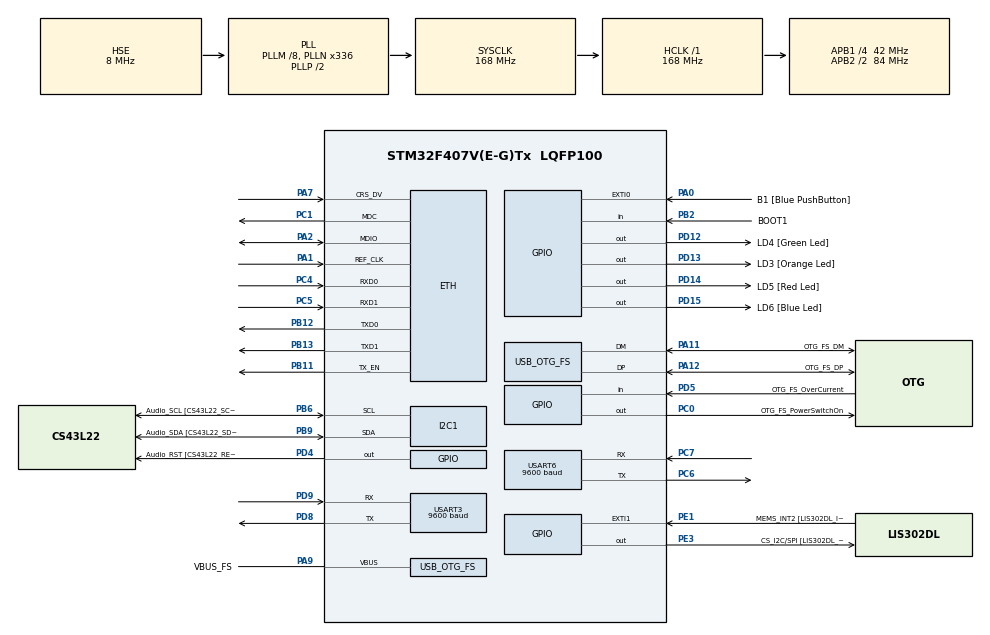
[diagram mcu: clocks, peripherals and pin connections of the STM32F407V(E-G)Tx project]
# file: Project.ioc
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ETH.MACAddr=00\:80\:E1\:00\:00\:01
ETH.MediaInterface=ETH_MEDIA_INTERFACE_RMII
ETH.PhyAddress=0
LWIP.GATEWAY_ADDRESS=192.168.001.254
LWIP.IP_ADDRESS=169.254.039.001
LWIP.LWIP_DHCP=0
LWIP.LWIP_HTTPD=1
LWIP.LWIP_HTTPD_CUSTOM_FILES=1
LWIP.LWIP_HTTPD_DYNAMIC_HEADERS=1
LWIP.NETMASK_ADDRESS=255.255.000.000
LWIP.Version=v2.0.3_Cube
Mcu.Family=STM32F4
Mcu.Name=STM32F407V(E-G)Tx
Mcu.Package=LQFP100
NVIC.OTG_FS_IRQn=true\:0\:0\:false\:false\:true\:true\:true
NVIC.PriorityGroup=NVIC_PRIORITYGROUP_0
NVIC.TIM2_IRQn=true\:0\:0\:false\:false\:true\:true\:true
NVIC.USART3_IRQn=true\:0\:0\:false\:false\:true\:true\:true
NVIC.USART6_IRQn=true\:0\:0\:false\:false\:true\:true\:true
PA0-WKUP.GPIO_Label=B1 [Blue PushButton]
PA0-WKUP.GPIO_ModeDefaultEXTI=GPIO_MODE_EVT_RISING
PA0-WKUP.GPIO_PuPd=GPIO_NOPULL
PA0-WKUP.Signal=GPXTI0
PA1.Mode=RMII
PA1.Signal=ETH_REF_CLK
PA10.GPIO_Label=OTG_FS_ID
PA10.GPIO_Mode=GPIO_MODE_AF_PP
PA10.GPIO_PuPd=GPIO_NOPULL
PA10.GPIO_Speed=GPIO_SPEED_FREQ_LOW
PA10.Signal=USB_OTG_FS_ID
PA11.GPIO_Label=OTG_FS_DM
PA11.GPIO_Mode=GPIO_MODE_AF_PP
PA11.GPIO_PuPd=GPIO_NOPULL
PA11.GPIO_Speed=GPIO_SPEED_FREQ_LOW
PA11.Mode=Host_Only
PA11.Signal=USB_OTG_FS_DM
PA12.GPIO_Label=OTG_FS_DP
PA12.GPIO_Mode=GPIO_MODE_AF_PP
PA12.GPIO_PuPd=GPIO_NOPULL
PA12.GPIO_Speed=GPIO_SPEED_FREQ_LOW
PA12.Mode=Host_Only
PA12.Signal=USB_OTG_FS_DP
PA13.GPIO_Label=SWDIO
PA13.Mode=Serial_Wire
PA13.Signal=SYS_JTMS-SWDIO
PA14.GPIO_Label=SWCLK
PA14.Mode=Serial_Wire
PA14.Signal=SYS_JTCK-SWCLK
PA2.Mode=RMII
PA2.Signal=ETH_MDIO
PA4.GPIO_Label=I2S3_WS [CS43L22_LRCK]
PA4.GPIO_Mode=GPIO_MODE_AF_PP
PA4.GPIO_PuPd=GPIO_NOPULL
PA4.GPIO_Speed=GPIO_SPEED_FREQ_LOW
PA4.Signal=I2S3_WS
PA5.GPIO_Label=SPI1_SCK [LIS302DL_SCL/SPC]
PA5.GPIO_Mode=GPIO_MODE_AF_PP
PA5.GPIO_PuPd=GPIO_NOPULL
PA5.GPIO_Speed=GPIO_SPEED_FREQ_LOW
PA5.Signal=SPI1_SCK
PA6.GPIO_Label=SPI1_MISO [LIS302DL_SDO]
PA6.GPIO_Mode=GPIO_MODE_AF_PP
PA6.GPIO_PuPd=GPIO_NOPULL
PA6.GPIO_Speed=GPIO_SPEED_FREQ_LOW
PA6.Signal=SPI1_MISO
PA7.Mode=RMII
PA7.Signal=ETH_CRS_DV
PA9.GPIO_Label=VBUS_FS
PA9.GPIO_Mode=GPIO_MODE_INPUT
PA9.GPIO_PuPd=GPIO_NOPULL
PA9.Mode=Activate_VBUS
PA9.Signal=USB_OTG_FS_VBUS
PB10.GPIO_Label=CLK_IN [MP45DT02_CLK]
PB10.GPIO_Mode=GPIO_MODE_AF_PP
PB10.GPIO_PuPd=GPIO_NOPULL
PB10.GPIO_Speed=GPIO_SPEED_FREQ_LOW
PB10.Signal=I2S2_CK
PB11.Mode=RMII
PB11.Signal=ETH_TX_EN
PB12.Mode=RMII
PB12.Signal=ETH_TXD0
PB13.Mode=RMII
PB13.Signal=ETH_TXD1
PB2.GPIO_Label=BOOT1
PB2.GPIO_Mode=GPIO_MODE_INPUT
PB2.GPIO_PuPd=GPIO_NOPULL
PB2.Signal=GPIO_Input
PB3.GPIO_Label=SWO
PB3.Signal=SYS_JTDO-SWO
PB6.GPIO_Label=Audio_SCL [CS43L22_SCL]
PB6.GPIO_Mode=GPIO_MODE_AF_OD
PB6.GPIO_PuPd=GPIO_NOPULL
PB6.GPIO_Speed=GPIO_SPEED_FREQ_LOW
PB6.Mode=I2C
PB6.Signal=I2C1_SCL
PB9.GPIO_Label=Audio_SDA [CS43L22_SDA]
PB9.GPIO_Mode=GPIO_MODE_AF_OD
PB9.GPIO_PuPd=GPIO_NOPULL
PB9.GPIO_Speed=GPIO_SPEED_FREQ_LOW
PB9.Mode=I2C
PB9.Signal=I2C1_SDA
PC0.GPIO_Label=OTG_FS_PowerSwitchOn
PC0.GPIO_PuPd=GPIO_NOPULL
PC0.GPIO_Speed=GPIO_SPEED_FREQ_LOW
PC0.PinState=GPIO_PIN_SET
PC0.Signal=GPIO_Output
PC1.Mode=RMII
PC1.Signal=ETH_MDC
PC10.GPIO_Label=I2S3_SCK [CS43L22_SCLK]
PC10.GPIO_Mode=GPIO_MODE_AF_PP
PC10.GPIO_PuPd=GPIO_NOPULL
PC10.GPIO_Speed=GPIO_SPEED_FREQ_LOW
PC10.Signal=I2S3_CK
PC12.GPIO_Label=I2S3_SD [CS43L22_SDIN]
PC12.GPIO_Mode=GPIO_MODE_AF_PP
PC12.GPIO_PuPd=GPIO_NOPULL
PC12.GPIO_Speed=GPIO_SPEED_FREQ_LOW
PC12.Signal=I2S3_SD
PC14-OSC32_IN.GPIO_Label=PC14-OSC32_IN
PC14-OSC32_IN.Mode=LSE-External-Oscillator
PC14-OSC32_IN.Signal=RCC_OSC32_IN
PC15-OSC32_OUT.GPIO_Label=PC15-OSC32_OUT
PC15-OSC32_OUT.Mode=LSE-External-Oscillator
PC15-OSC32_OUT.Signal=RCC_OSC32_OUT
PC3.GPIO_Label=PDM_OUT [MP45DT02_DOUT]
PC3.GPIO_Mode=GPIO_MODE_AF_PP
PC3.GPIO_PuPd=GPIO_NOPULL
PC3.GPIO_Speed=GPIO_SPEED_FREQ_LOW
PC3.Signal=I2S2_SD
PC4.Mode=RMII
PC4.Signal=ETH_RXD0
PC5.Mode=RMII
PC5.Signal=ETH_RXD1
PC6.Mode=Asynchronous
PC6.Signal=USART6_TX
PC7.Mode=Asynchronous
PC7.Signal=USART6_RX
PD12.GPIO_Label=LD4 [Green Led]
PD12.GPIO_PuPd=GPIO_NOPULL
PD12.GPIO_Speed=GPIO_SPEED_FREQ_LOW
PD12.Signal=GPIO_Output
PD13.GPIO_Label=LD3 [Orange Led]
PD13.GPIO_PuPd=GPIO_NOPULL
PD13.GPIO_Speed=GPIO_SPEED_FREQ_LOW
PD13.Signal=GPIO_Output
PD14.GPIO_Label=LD5 [Red Led]
PD14.GPIO_PuPd=GPIO_NOPULL
PD14.GPIO_Speed=GPIO_SPEED_FREQ_LOW
PD14.Signal=GPIO_Output
PD15.GPIO_Label=LD6 [Blue Led]
PD15.GPIO_PuPd=GPIO_NOPULL
PD15.GPIO_Speed=GPIO_SPEED_FREQ_LOW
PD15.Signal=GPIO_Output
PD4.GPIO_Label=Audio_RST [CS43L22_RESET]
PD4.GPIO_PuPd=GPIO_NOPULL
PD4.GPIO_Speed=GPIO_SPEED_FREQ_LOW
PD4.Signal=GPIO_Output
PD5.GPIO_Label=OTG_FS_OverCurrent
PD5.GPIO_Mode=GPIO_MODE_INPUT
PD5.GPIO_PuPd=GPIO_NOPULL
PD5.Signal=GPIO_Input
PD8.Mode=Asynchronous
PD8.Signal=USART3_TX
PD9.Mode=Asynchronous
PD9.Signal=USART3_RX
PE1.GPIO_Label=MEMS_INT2 [LIS302DL_INT2]
PE1.GPIO_ModeDefaultEXTI=GPIO_MODE_EVT_RISING
PE1.GPIO_PuPd=GPIO_NOPULL
PE1.Signal=GPXTI1
PE3.GPIO_Label=CS_I2C/SPI [LIS302DL_CS_I2C/SPI]
PE3.GPIO_PuPd=GPIO_NOPULL
PE3.GPIO_Speed=GPIO_SPEED_FREQ_LOW
PE3.Signal=GPIO_Output
PH0-OSC_IN.GPIO_Label=PH0-OSC_IN
PH0-OSC_IN.Mode=HSE-External-Oscillator
PH0-OSC_IN.Signal=RCC_OSC_IN
PH1-OSC_OUT.GPIO_Label=PH1-OSC_OUT
PH1-OSC_OUT.Mode=HSE-External-Oscillator
PH1-OSC_OUT.Signal=RCC_OSC_OUT
ProjectManager.HeapSize=0x200
ProjectManager.StackSize=0x400
ProjectManager.TargetToolchain=TrueSTUDIO
RCC.48MHZClocksFreq_Value=48000000
RCC.AHBFreq_Value=168000000
RCC.APB1CLKDivider=RCC_HCLK_DIV4
RCC.APB1Freq_Value=42000000
RCC.APB1TimFreq_Value=84000000
RCC.APB2CLKDivider=RCC_HCLK_DIV2
RCC.APB2Freq_Value=84000000
RCC.APB2TimFreq_Value=168000000
RCC.CortexFreq_Value=168000000
RCC.HCLKFreq_Value=168000000
RCC.HSE_VALUE=8000000
RCC.HSI_VALUE=16000000
RCC.PLLM=8
RCC.PLLN=336
RCC.PLLQ=7
RCC.SYSCLKFreq_VALUE=168000000
RCC.SYSCLKSource=RCC_SYSCLKSOURCE_PLLCLK
RCC.VCOOutputFreq_Value=336000000
TIM2.Period=4999
TIM2.Prescaler=8399
USART3.BaudRate=9600
USART3.VirtualMode=VM_ASYNC
USART6.BaudRate=9600
USART6.VirtualMode=VM_ASYNC
USB_HOST.BSP.number=1
USB_HOST.USBH_HandleTypeDef-CDC_FS=hUsbHostFS
USB_HOST.VirtualModeFS=Cdc
USB_HOST0.BSP.STBoard=false
USB_HOST0.BSP.api=Unknown
USB_HOST0.BSP.i2caddr=0
USB_HOST0.BSP.i2creg=0
USB_HOST0.BSP.instance=PC0
USB_HOST0.BSP.ip=GPIO
USB_HOST0.BSP.mode=Output
USB_HOST0.BSP.name=Drive_VBUS_FS
USB_HOST0.BSP.solution=PC0
USB_OTG_FS.VirtualMode=Host_Only
USB_OTG_FS.phy_itface=HCD_PHY_EMBEDDED
VP_LWIP_VS_Enabled.Mode=Enabled
VP_TIM2_VS_ClockSourceINT.Mode=Internal
VP_USB_HOST_VS_USB_HOST_CDC_FS.Mode=CDC_FS
board=STM32F407G-DISC1

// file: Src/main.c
/* USER CODE BEGIN Header */
/**
  ******************************************************************************
  * @file           : main.c
  * @brief          : Main program body
  ******************************************************************************
  * @attention
  *
  * <h2><center>&copy; Copyright (c) 2019 STMicroelectronics.
  * All rights reserved.</center></h2>
  *
  * This software component is licensed by ST under Ultimate Liberty license
  * SLA0044, the "License"; You may not use this file except in compliance with
  * the License. You may obtain a copy of the License at:
  *                             www.st.com/SLA0044
  *
  ******************************************************************************
  */
/* USER CODE END Header */

#include "main.h"
#include "lwip.h"
#include "usb_host.h"

/* USER CODE BEGIN Includes */
#include <stdio.h>
#include "httpd.h"
#include <string.h>

/* USER CODE END Includes */

I2C_HandleTypeDef hi2c1;

TIM_HandleTypeDef htim2;

UART_HandleTypeDef huart3;
UART_HandleTypeDef huart6;

void SystemClock_Config(void);
static void MX_GPIO_Init(void);
static void MX_I2C1_Init(void);
static void MX_TIM2_Init(void);
static void MX_USART6_UART_Init(void);
static void MX_USART3_UART_Init(void);
void MX_USB_HOST_Process(void);

int main(void)
{

  /* MCU Configuration--------------------------------------------------------*/

  /* Reset of all peripherals, Initializes the Flash interface and the Systick. */
  HAL_Init();

  /* Configure the system clock */
  SystemClock_Config();

  /* Initialize all configured peripherals */
  MX_GPIO_Init();
  MX_I2C1_Init();
  MX_TIM2_Init();
  MX_USART6_UART_Init();
  MX_LWIP_Init();
  MX_USB_HOST_Init();
  MX_USART3_UART_Init();

  /* Infinite loop */
  /* USER CODE BEGIN WHILE */
  httpd_init();

  // Initialize data
  uint16_t size = 12;
  uint8_t data[size];

  while (1)
  {
    /* USER CODE END WHILE */
    MX_USB_HOST_Process();

    /* USER CODE BEGIN 3 */

    // Make ETH work
    MX_LWIP_Process();

    // Receive data from UART3 (accelerometre)
    memset(data, 0, size);
	HAL_UART_Receive(&huart3, data, size, 1000);
	if (strcmp((char*) data, "Hello world\n") == 0)
	{
		// Light green led to test reception
		HAL_GPIO_TogglePin(GPIOD, LD4_Pin);
	}

    // Receive data from UART6
    /*memset(data, 0, size);
    HAL_UART_Receive(&huart6, data, size, 1000);
    if (data[0] != 0)
    {
    	// Light green led to test reception
    	HAL_GPIO_TogglePin(GPIOD, LD4_Pin);
    }*/

  }
  /* USER CODE END 3 */
}

void SystemClock_Config(void)
{
  RCC_OscInitTypeDef RCC_OscInitStruct = {0};
  RCC_ClkInitTypeDef RCC_ClkInitStruct = {0};

  /** Configure the main internal regulator output voltage
  */
  __HAL_RCC_PWR_CLK_ENABLE();
  __HAL_PWR_VOLTAGESCALING_CONFIG(PWR_REGULATOR_VOLTAGE_SCALE1);
  /** Initializes the CPU, AHB and APB busses clocks
  */
  RCC_OscInitStruct.OscillatorType = RCC_OSCILLATORTYPE_HSE;
  RCC_OscInitStruct.HSEState = RCC_HSE_ON;
  RCC_OscInitStruct.PLL.PLLState = RCC_PLL_ON;
  RCC_OscInitStruct.PLL.PLLSource = RCC_PLLSOURCE_HSE;
  RCC_OscInitStruct.PLL.PLLM = 8;
  RCC_OscInitStruct.PLL.PLLN = 336;
  RCC_OscInitStruct.PLL.PLLP = RCC_PLLP_DIV2;
  RCC_OscInitStruct.PLL.PLLQ = 7;
  if (HAL_RCC_OscConfig(&RCC_OscInitStruct) != HAL_OK)
  {
    Error_Handler();
  }
  /** Initializes the CPU, AHB and APB busses clocks
  */
  RCC_ClkInitStruct.ClockType = RCC_CLOCKTYPE_HCLK|RCC_CLOCKTYPE_SYSCLK
                              |RCC_CLOCKTYPE_PCLK1|RCC_CLOCKTYPE_PCLK2;
  RCC_ClkInitStruct.SYSCLKSource = RCC_SYSCLKSOURCE_PLLCLK;
  RCC_ClkInitStruct.AHBCLKDivider = RCC_SYSCLK_DIV1;
  RCC_ClkInitStruct.APB1CLKDivider = RCC_HCLK_DIV4;
  RCC_ClkInitStruct.APB2CLKDivider = RCC_HCLK_DIV2;

  if (HAL_RCC_ClockConfig(&RCC_ClkInitStruct, FLASH_LATENCY_5) != HAL_OK)
  {
    Error_Handler();
  }
}

static void MX_I2C1_Init(void)
{

  hi2c1.Instance = I2C1;
  hi2c1.Init.ClockSpeed = 100000;
  hi2c1.Init.DutyCycle = I2C_DUTYCYCLE_2;
  hi2c1.Init.OwnAddress1 = 0;
  hi2c1.Init.AddressingMode = I2C_ADDRESSINGMODE_7BIT;
  hi2c1.Init.DualAddressMode = I2C_DUALADDRESS_DISABLE;
  hi2c1.Init.OwnAddress2 = 0;
  hi2c1.Init.GeneralCallMode = I2C_GENERALCALL_DISABLE;
  hi2c1.Init.NoStretchMode = I2C_NOSTRETCH_DISABLE;
  if (HAL_I2C_Init(&hi2c1) != HAL_OK)
  {
    Error_Handler();
  }

}

static void MX_TIM2_Init(void)
{

  TIM_ClockConfigTypeDef sClockSourceConfig = {0};
  TIM_MasterConfigTypeDef sMasterConfig = {0};

  htim2.Instance = TIM2;
  htim2.Init.Prescaler = 8399;
  htim2.Init.CounterMode = TIM_COUNTERMODE_UP;
  htim2.Init.Period = 4999;
  htim2.Init.ClockDivision = TIM_CLOCKDIVISION_DIV1;
  htim2.Init.AutoReloadPreload = TIM_AUTORELOAD_PRELOAD_DISABLE;
  if (HAL_TIM_Base_Init(&htim2) != HAL_OK)
  {
    Error_Handler();
  }
  sClockSourceConfig.ClockSource = TIM_CLOCKSOURCE_INTERNAL;
  if (HAL_TIM_ConfigClockSource(&htim2, &sClockSourceConfig) != HAL_OK)
  {
    Error_Handler();
  }
  sMasterConfig.MasterOutputTrigger = TIM_TRGO_RESET;
  sMasterConfig.MasterSlaveMode = TIM_MASTERSLAVEMODE_DISABLE;
  if (HAL_TIMEx_MasterConfigSynchronization(&htim2, &sMasterConfig) != HAL_OK)
  {
    Error_Handler();
  }

}

static void MX_USART3_UART_Init(void)
{

  huart3.Instance = USART3;
  huart3.Init.BaudRate = 9600;
  huart3.Init.WordLength = UART_WORDLENGTH_8B;
  huart3.Init.StopBits = UART_STOPBITS_1;
  huart3.Init.Parity = UART_PARITY_NONE;
  huart3.Init.Mode = UART_MODE_TX_RX;
  huart3.Init.HwFlowCtl = UART_HWCONTROL_NONE;
  huart3.Init.OverSampling = UART_OVERSAMPLING_16;
  if (HAL_UART_Init(&huart3) != HAL_OK)
  {
    Error_Handler();
  }

}

static void MX_USART6_UART_Init(void)
{

  huart6.Instance = USART6;
  huart6.Init.BaudRate = 9600;
  huart6.Init.WordLength = UART_WORDLENGTH_8B;
  huart6.Init.StopBits = UART_STOPBITS_1;
  huart6.Init.Parity = UART_PARITY_NONE;
  huart6.Init.Mode = UART_MODE_TX_RX;
  huart6.Init.HwFlowCtl = UART_HWCONTROL_NONE;
  huart6.Init.OverSampling = UART_OVERSAMPLING_16;
  if (HAL_UART_Init(&huart6) != HAL_OK)
  {
    Error_Handler();
  }

}

static void MX_GPIO_Init(void)
{
  GPIO_InitTypeDef GPIO_InitStruct = {0};

  /* GPIO Ports Clock Enable */
  __HAL_RCC_GPIOE_CLK_ENABLE();
  __HAL_RCC_GPIOC_CLK_ENABLE();
  __HAL_RCC_GPIOH_CLK_ENABLE();
  __HAL_RCC_GPIOA_CLK_ENABLE();
  __HAL_RCC_GPIOB_CLK_ENABLE();
  __HAL_RCC_GPIOD_CLK_ENABLE();

  /*Configure GPIO pin Output Level */
  HAL_GPIO_WritePin(CS_I2C_SPI_GPIO_Port, CS_I2C_SPI_Pin, GPIO_PIN_RESET);

  /*Configure GPIO pin Output Level */
  HAL_GPIO_WritePin(OTG_FS_PowerSwitchOn_GPIO_Port, OTG_FS_PowerSwitchOn_Pin, GPIO_PIN_SET);

  /*Configure GPIO pin Output Level */
  HAL_GPIO_WritePin(GPIOD, LD4_Pin|LD3_Pin|LD5_Pin|LD6_Pin
                          |Audio_RST_Pin, GPIO_PIN_RESET);

  /*Configure GPIO pin : CS_I2C_SPI_Pin */
  GPIO_InitStruct.Pin = CS_I2C_SPI_Pin;
  GPIO_InitStruct.Mode = GPIO_MODE_OUTPUT_PP;
  GPIO_InitStruct.Pull = GPIO_NOPULL;
  GPIO_InitStruct.Speed = GPIO_SPEED_FREQ_LOW;
  HAL_GPIO_Init(CS_I2C_SPI_GPIO_Port, &GPIO_InitStruct);

  /*Configure GPIO pin : OTG_FS_PowerSwitchOn_Pin */
  GPIO_InitStruct.Pin = OTG_FS_PowerSwitchOn_Pin;
  GPIO_InitStruct.Mode = GPIO_MODE_OUTPUT_PP;
  GPIO_InitStruct.Pull = GPIO_NOPULL;
  GPIO_InitStruct.Speed = GPIO_SPEED_FREQ_LOW;
  HAL_GPIO_Init(OTG_FS_PowerSwitchOn_GPIO_Port, &GPIO_InitStruct);

  /*Configure GPIO pin : PDM_OUT_Pin */
  GPIO_InitStruct.Pin = PDM_OUT_Pin;
  GPIO_InitStruct.Mode = GPIO_MODE_AF_PP;
  GPIO_InitStruct.Pull = GPIO_NOPULL;
  GPIO_InitStruct.Speed = GPIO_SPEED_FREQ_LOW;
  GPIO_InitStruct.Alternate = GPIO_AF5_SPI2;
  HAL_GPIO_Init(PDM_OUT_GPIO_Port, &GPIO_InitStruct);

  /*Configure GPIO pin : B1_Pin */
  GPIO_InitStruct.Pin = B1_Pin;
  GPIO_InitStruct.Mode = GPIO_MODE_EVT_RISING;
  GPIO_InitStruct.Pull = GPIO_NOPULL;
  HAL_GPIO_Init(B1_GPIO_Port, &GPIO_InitStruct);

  /*Configure GPIO pin : I2S3_WS_Pin */
  GPIO_InitStruct.Pin = I2S3_WS_Pin;
  GPIO_InitStruct.Mode = GPIO_MODE_AF_PP;
  GPIO_InitStruct.Pull = GPIO_NOPULL;
  GPIO_InitStruct.Speed = GPIO_SPEED_FREQ_LOW;
  GPIO_InitStruct.Alternate = GPIO_AF6_SPI3;
  HAL_GPIO_Init(I2S3_WS_GPIO_Port, &GPIO_InitStruct);

  /*Configure GPIO pins : SPI1_SCK_Pin SPI1_MISO_Pin */
  GPIO_InitStruct.Pin = SPI1_SCK_Pin|SPI1_MISO_Pin;
  GPIO_InitStruct.Mode = GPIO_MODE_AF_PP;
  GPIO_InitStruct.Pull = GPIO_NOPULL;
  GPIO_InitStruct.Speed = GPIO_SPEED_FREQ_LOW;
  GPIO_InitStruct.Alternate = GPIO_AF5_SPI1;
  HAL_GPIO_Init(GPIOA, &GPIO_InitStruct);

  /*Configure GPIO pin : BOOT1_Pin */
  GPIO_InitStruct.Pin = BOOT1_Pin;
  GPIO_InitStruct.Mode = GPIO_MODE_INPUT;
  GPIO_InitStruct.Pull = GPIO_NOPULL;
  HAL_GPIO_Init(BOOT1_GPIO_Port, &GPIO_InitStruct);

  /*Configure GPIO pin : CLK_IN_Pin */
  GPIO_InitStruct.Pin = CLK_IN_Pin;
  GPIO_InitStruct.Mode = GPIO_MODE_AF_PP;
  GPIO_InitStruct.Pull = GPIO_NOPULL;
  GPIO_InitStruct.Speed = GPIO_SPEED_FREQ_LOW;
  GPIO_InitStruct.Alternate = GPIO_AF5_SPI2;
  HAL_GPIO_Init(CLK_IN_GPIO_Port, &GPIO_InitStruct);

  /*Configure GPIO pins : LD4_Pin LD3_Pin LD5_Pin LD6_Pin
                           Audio_RST_Pin */
  GPIO_InitStruct.Pin = LD4_Pin|LD3_Pin|LD5_Pin|LD6_Pin
                          |Audio_RST_Pin;
  GPIO_InitStruct.Mode = GPIO_MODE_OUTPUT_PP;
  GPIO_InitStruct.Pull = GPIO_NOPULL;
  GPIO_InitStruct.Speed = GPIO_SPEED_FREQ_LOW;
  HAL_GPIO_Init(GPIOD, &GPIO_InitStruct);

  /*Configure GPIO pins : I2S3_SCK_Pin I2S3_SD_Pin */
  GPIO_InitStruct.Pin = I2S3_SCK_Pin|I2S3_SD_Pin;
  GPIO_InitStruct.Mode = GPIO_MODE_AF_PP;
  GPIO_InitStruct.Pull = GPIO_NOPULL;
  GPIO_InitStruct.Speed = GPIO_SPEED_FREQ_LOW;
  GPIO_InitStruct.Alternate = GPIO_AF6_SPI3;
  HAL_GPIO_Init(GPIOC, &GPIO_InitStruct);

  /*Configure GPIO pin : OTG_FS_OverCurrent_Pin */
  GPIO_InitStruct.Pin = OTG_FS_OverCurrent_Pin;
  GPIO_InitStruct.Mode = GPIO_MODE_INPUT;
  GPIO_InitStruct.Pull = GPIO_NOPULL;
  HAL_GPIO_Init(OTG_FS_OverCurrent_GPIO_Port, &GPIO_InitStruct);

  /*Configure GPIO pin : MEMS_INT2_Pin */
  GPIO_InitStruct.Pin = MEMS_INT2_Pin;
  GPIO_InitStruct.Mode = GPIO_MODE_EVT_RISING;
  GPIO_InitStruct.Pull = GPIO_NOPULL;
  HAL_GPIO_Init(MEMS_INT2_GPIO_Port, &GPIO_InitStruct);

}

void Error_Handler(void)
{
}

/************************ (C) COPYRIGHT STMicroelectronics *****END OF FILE****/
